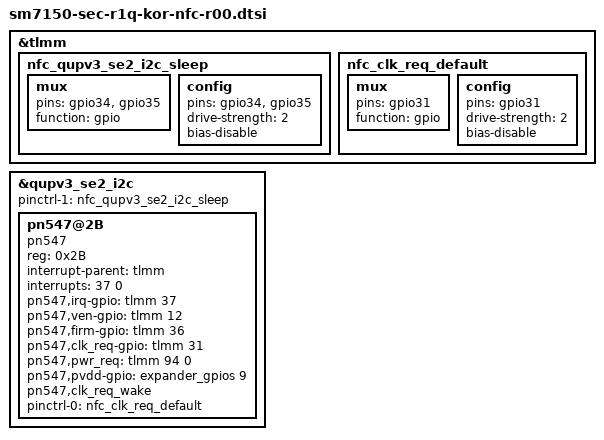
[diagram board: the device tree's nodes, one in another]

/* Copyright (c) 2016-2017, The Linux Foundation. All rights reserved.
 *
 * This program is free software; you can redistribute it and/or modify
 * it under the terms of the GNU General Public License version 2 and
 * only version 2 as published by the Free Software Foundation.
 *
 * This program is distributed in the hope that it will be useful,
 * but WITHOUT ANY WARRANTY; without even the implied warranty of
 * MERCHANTABILITY or FITNESS FOR A PARTICULAR PURPOSE.  See the
 * GNU General Public License for more details.
 */
/*
/ {
	aliases {
		spi2 = &qupv3_se1_spi;
	};
};
*/

&tlmm {
	nfc_qupv3_se2_i2c_sleep: nfc_qupv3_se2_i2c_sleep {
		mux {
			pins = "gpio34", "gpio35";
			function = "gpio";
		};
	
		config {
			pins = "gpio34", "gpio35";
			drive-strength = <2>;
			bias-disable;
		};
	};

	nfc_clk_req_default: nfc_clk_req_default {
		/* active state */
		mux {
			/* GPIO 31: NFC CLOCK REQUEST */
			pins = "gpio31";
			function = "gpio";
		};

		config {
			pins = "gpio31";
			drive-strength = <2>; /* 2 MA */
			bias-disable;
		};
	};
};

/* gpio34 and gpio35 are used for nfc i2c */
&qupv3_se2_i2c { 
	status = "okay";
	pinctrl-1 = <&nfc_qupv3_se2_i2c_sleep>;

	pn547@2B {
		compatible = "pn547";
		reg = <0x2B>;
		interrupt-parent = <&tlmm>;
		interrupts = <37 0>;
		pn547,irq-gpio = <&tlmm 37 0>;
		pn547,ven-gpio = <&tlmm 12 0>;
		pn547,firm-gpio = <&tlmm 36 0>;
		pn547,clk_req-gpio = <&tlmm 31 0>; /* BBCLK3 is controled by gpio 31 */
		pn547,pwr_req =  <&tlmm 94 0>;
		pn547,pvdd-gpio = <&expander_gpios 9 0>;
		pn547,clk_req_wake;
		pinctrl-names = "default";
		pinctrl-0 = <&nfc_clk_req_default>;
	};
};
